VERSION ""

NS_ :

BS_:

BU_: STEER DAS HANDCART STEER BMS_HV BMS_HV HANDCART HANDCART BMS_HV BMS_HV HANDCART DAS BMS_HV HANDCART HANDCART BMS_HV HANDCART BMS_HV STEER DAS HANDCART BMS_HV BMS_HV STEER HANDCART DAS BMS_HV BMS_HV HANDCART STEER BRUSA BMS_HV DAS HANDCART BMS_HV DAS HANDCART INVERTER_L BMS_HV DAS HANDCART INVERTER_L BMS_HV INVERTER_L BMS_HV DAS HANDCART INVERTER_L BMS_HV DAS HANDCART STEER HANDCART DAS STEER BMS_HV DAS HANDCART BMS_HV BMS_HV HANDCART HANDCART STEER HANDCART DAS BMS_HV BMS_HV TLM TLM HANDCART STEER HANDCART STEER TLM BMS_HV DAS STEER HANDCART BMS_HV DAS BMS_HV HANDCART HANDCART TLM STEER STEER DAS STEER BMS_HV DAS TLM BMS_HV STEER TLM STEER STEER TLM DAS TLM BMS_LV STEER TLM BMS_LV STEER BMS_HV DAS TLM BMS_LV DAS STEER STEER DAS DATA_LOGGER BMS_LV BMS_LV BMS_LV BMS_HV DAS TLM BMS_LV STEER STEER DAS BMS_LV BMS_LV STEER BMS_HV STEER DAS DAS STEER BMS_LV TLM STEER STEER DAS DAS HANDCART BRUSA BRUSA BMS_LV TLM HANDCART STEER STEER BRUSA DAS DAS HANDCART BMS_LV BMS_LW BRUSA STEER STEER BMS_HV DAS DAS HANDCART BMS_LV BMS_HW BMS_HV STEER STEER HANDCART DAS DAS BMS_HV BMS_LV DAS HANDCART STEER STEER BMS_HV DAS DAS HANDCART STEER STEER BMS_HV DAS BMS_LV HANDCART DAS HANDCART BMS_HV STEER BMS_HV HANDCART DAS HANDCART BMS_HV HANDCART BMS_HV BRUSA STEER HANDCART DAS HANDCART

BO_ 3 BMS_HV_JMP_TO_BLT: 0 Vector__XXX

BO_ 35 BMS_LV_JMP_TO_BLT: 0 Vector__XXX

BO_ 1029 STEER_VERSION: 5 Vector__XXX
 SG_ canlib_build_time : 8|32@1+ (1,0) [0|4294967295] "" Vector__XXX
 SG_ component_version : 0|8@1+ (1,0) [0|255] "" Vector__XXX

BO_ 1061 DAS_VERSION: 5 Vector__XXX
 SG_ canlib_build_time : 8|32@1+ (1,0) [0|4294967295] "" Vector__XXX
 SG_ component_version : 0|8@1+ (1,0) [0|255] "" Vector__XXX

BO_ 1093 HV_VERSION: 5 Vector__XXX
 SG_ canlib_build_time : 8|32@1+ (1,0) [0|4294967295] "" Vector__XXX
 SG_ component_version : 0|8@1+ (1,0) [0|255] "" Vector__XXX

BO_ 1125 LV_VERSION: 5 Vector__XXX
 SG_ canlib_build_time : 8|32@1+ (1,0) [0|4294967295] "" Vector__XXX
 SG_ component_version : 0|8@1+ (1,0) [0|255] "" Vector__XXX

BO_ 1157 TLM_VERSION: 5 Vector__XXX
 SG_ canlib_build_time : 8|32@1+ (1,0) [0|4294967295] "" Vector__XXX
 SG_ component_version : 0|8@1+ (1,0) [0|255] "" Vector__XXX

BO_ 261 TIMESTAMP: 4 Vector__XXX
 SG_ timestamp : 0|32@1+ (1,0) [0|4294967295] "" Vector__XXX

BO_ 293 AMBIENT_TEMPERATURE: 2 Vector__XXX
 SG_ temp : 0|16@1- (1,-32768) [-32768|32767] "" Vector__XXX

BO_ 1072 DATA_LOGGER: 8 Vector__XXX
 SG_ placeholder2 : 32|32@1+ (1,0) [0|4294967295] "" Vector__XXX
 SG_ placeholder1 : 0|32@1+ (1,0) [0|4294967295] "" Vector__XXX

BO_ 256 SET_TLM_STATUS: 1 Vector__XXX
 SG_ tlm_status : 0|1@1+ (1,0) [0|1] "" Vector__XXX

BO_ 262 TLM_STATUS: 1 Vector__XXX
 SG_ tlm_status : 0|1@1+ (1,0) [0|1] "" Vector__XXX

BO_ 1792 STEER_SYSTEM_STATUS: 1 Vector__XXX
 SG_ soc_temp : 0|8@1+ (1,0) [0|255] "" Vector__XXX

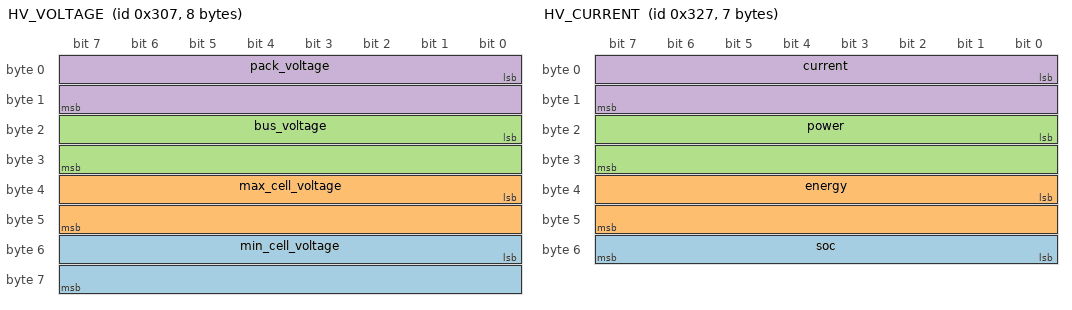
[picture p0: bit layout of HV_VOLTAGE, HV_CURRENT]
BO_ 775 HV_VOLTAGE: 8 Vector__XXX
 SG_ min_cell_voltage : 48|16@1+ (7.629510948348211e-05,0) [0|5] "" Vector__XXX
 SG_ max_cell_voltage : 32|16@1+ (7.629510948348211e-05,0) [0|5] "" Vector__XXX
 SG_ bus_voltage : 16|16@1+ (0.007019150072480354,0) [0|460] "" Vector__XXX
 SG_ pack_voltage : 0|16@1+ (0.007019150072480354,0) [0|460] "" Vector__XXX

BO_ 807 HV_CURRENT: 7 Vector__XXX
 SG_ soc : 48|8@1+ (0.39215686274509803,0) [0|100] "" Vector__XXX
 SG_ energy : 32|16@1+ (0.10681315327687495,0) [0|7000] "" Vector__XXX
 SG_ power : 16|16@1+ (0.0015259021896696422,0) [0|100] "" Vector__XXX
 SG_ current : 0|16@1+ (0.0032043945983062485,-10) [-10|200] "" Vector__XXX

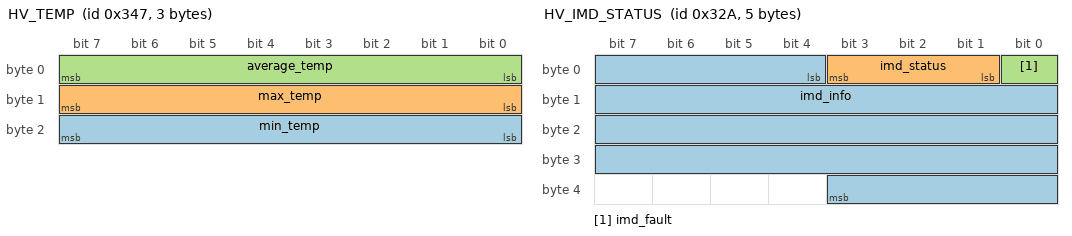
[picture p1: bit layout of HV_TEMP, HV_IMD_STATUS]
BO_ 839 HV_TEMP: 3 Vector__XXX
 SG_ min_temp : 16|8@1+ (0.39215686274509803,-20) [-20|80] "" Vector__XXX
 SG_ max_temp : 8|8@1+ (0.39215686274509803,-20) [-20|80] "" Vector__XXX
 SG_ average_temp : 0|8@1+ (0.39215686274509803,-20) [-20|80] "" Vector__XXX

BO_ 7 HV_ERRORS: 4 Vector__XXX
 SG_ errors_EEPROM_WRITE : 27|1@1+ (1,0) [0|0] "" Vector__XXX
 SG_ errors_EEPROM_COMM : 26|1@1+ (1,0) [0|0] "" Vector__XXX
 SG_ errors_FEEDBACK_CIRCUITRY : 25|1@1+ (1,0) [0|0] "" Vector__XXX
 SG_ errors_FEEDBACK : 24|1@1+ (1,0) [0|0] "" Vector__XXX
 SG_ errors_CELLBOARD_INTERNAL : 23|1@1+ (1,0) [0|0] "" Vector__XXX
 SG_ errors_CELLBOARD_COMM : 22|1@1+ (1,0) [0|0] "" Vector__XXX
 SG_ errors_INT_VOLTAGE_MISMATCH : 21|1@1+ (1,0) [0|0] "" Vector__XXX
 SG_ errors_CAN : 20|1@1+ (1,0) [0|0] "" Vector__XXX
 SG_ errors_OVER_CURRENT : 19|1@1+ (1,0) [0|0] "" Vector__XXX
 SG_ errors_CELL_OVER_TEMPERATURE : 18|1@1+ (1,0) [0|0] "" Vector__XXX
 SG_ errors_CELL_HIGH_TEMPERATURE : 17|1@1+ (1,0) [0|0] "" Vector__XXX
 SG_ errors_CELL_OVER_VOLTAGE : 16|1@1+ (1,0) [0|0] "" Vector__XXX
 SG_ errors_CELL_UNDER_VOLTAGE : 15|1@1+ (1,0) [0|0] "" Vector__XXX
 SG_ errors_CELL_LOW_VOLTAGE : 14|1@1+ (1,0) [0|0] "" Vector__XXX
 SG_ warnings_EEPROM_WRITE : 13|1@1+ (1,0) [0|0] "" Vector__XXX
 SG_ warnings_EEPROM_COMM : 12|1@1+ (1,0) [0|0] "" Vector__XXX
 SG_ warnings_FEEDBACK_CIRCUITRY : 11|1@1+ (1,0) [0|0] "" Vector__XXX
 SG_ warnings_FEEDBACK : 10|1@1+ (1,0) [0|0] "" Vector__XXX
 SG_ warnings_CELLBOARD_INTERNAL : 9|1@1+ (1,0) [0|0] "" Vector__XXX
 SG_ warnings_CELLBOARD_COMM : 8|1@1+ (1,0) [0|0] "" Vector__XXX
 SG_ warnings_INT_VOLTAGE_MISMATCH : 7|1@1+ (1,0) [0|0] "" Vector__XXX
 SG_ warnings_CAN : 6|1@1+ (1,0) [0|0] "" Vector__XXX
 SG_ warnings_OVER_CURRENT : 5|1@1+ (1,0) [0|0] "" Vector__XXX
 SG_ warnings_CELL_OVER_TEMPERATURE : 4|1@1+ (1,0) [0|0] "" Vector__XXX
 SG_ warnings_CELL_HIGH_TEMPERATURE : 3|1@1+ (1,0) [0|0] "" Vector__XXX
 SG_ warnings_CELL_OVER_VOLTAGE : 2|1@1+ (1,0) [0|0] "" Vector__XXX
 SG_ warnings_CELL_UNDER_VOLTAGE : 1|1@1+ (1,0) [0|0] "" Vector__XXX
 SG_ warnings_CELL_LOW_VOLTAGE : 0|1@1+ (1,0) [0|0] "" Vector__XXX

BO_ 1 HV_CAN_FORWARD: 1 Vector__XXX
 SG_ can_forward_set : 0|1@1+ (1,0) [0|1] "" Vector__XXX

BO_ 33 HV_FANS_OVERRIDE: 3 Vector__XXX
 SG_ fans_speed : 1|16@1+ (1.5259021896696422e-05,0) [0|1] "" Vector__XXX
 SG_ fans_override : 0|1@1+ (1,0) [0|1] "" Vector__XXX

BO_ 4 HV_CAN_FORWARD_STATUS: 1 Vector__XXX
 SG_ can_forward_status : 0|1@1+ (1,0) [0|1] "" Vector__XXX

BO_ 772 HV_FANS_OVERRIDE_STATUS: 3 Vector__XXX
 SG_ fans_speed : 1|16@1+ (1.5259021896696422e-05,0) [0|1] "" Vector__XXX
 SG_ fans_override : 0|1@1+ (1,0) [0|1] "" Vector__XXX

BO_ 778 HV_FEEDBACKS_STATUS: 5 Vector__XXX
 SG_ is_circuitry_error_FEEDBACK_SD_END : 37|1@1+ (1,0) [0|0] "" Vector__XXX
 SG_ is_circuitry_error_FEEDBACK_IMD_FAULT : 36|1@1+ (1,0) [0|0] "" Vector__XXX
 SG_ is_circuitry_error_FEEDBACK_RELAY_SD : 35|1@1+ (1,0) [0|0] "" Vector__XXX
 SG_ is_circuitry_error_FEEDBACK_SD_OUT : 34|1@1+ (1,0) [0|0] "" Vector__XXX
 SG_ is_circuitry_error_FEEDBACK_SD_IN : 33|1@1+ (1,0) [0|0] "" Vector__XXX
 SG_ is_circuitry_error_FEEDBACK_CHECK_MUX : 32|1@1+ (1,0) [0|0] "" Vector__XXX
 SG_ is_circuitry_error_FEEDBACK_TSP_OVER_60V_STATUS : 31|1@1+ (1,0) [0|0] "" Vector__XXX
 SG_ is_circuitry_error_FEEDBACK_PRECHARGE_STATUS : 30|1@1+ (1,0) [0|0] "" Vector__XXX
 SG_ is_circuitry_error_FEEDBACK_AIRN_GATE : 29|1@1+ (1,0) [0|0] "" Vector__XXX
 SG_ is_circuitry_error_FEEDBACK_AIRP_GATE : 28|1@1+ (1,0) [0|0] "" Vector__XXX
 SG_ is_circuitry_error_FEEDBACK_AIRP_STATUS : 27|1@1+ (1,0) [0|0] "" Vector__XXX
 SG_ is_circuitry_error_FEEDBACK_AIRN_STATUS : 26|1@1+ (1,0) [0|0] "" Vector__XXX
 SG_ is_circuitry_error_FEEDBACK_TS_OVER_60V_STATUS : 25|1@1+ (1,0) [0|0] "" Vector__XXX
 SG_ is_circuitry_error_FEEDBACK_TSAL_GREEN : 24|1@1+ (1,0) [0|0] "" Vector__XXX
 SG_ is_circuitry_error_FEEDBACK_EXT_LATCHED : 23|1@1+ (1,0) [0|0] "" Vector__XXX
 SG_ is_circuitry_error_FEEDBACK_BMS_LATCHED : 22|1@1+ (1,0) [0|0] "" Vector__XXX
 SG_ is_circuitry_error_FEEDBACK_TSAL_GREEN_FAULT_LATCHED : 21|1@1+ (1,0) [0|0] "" Vector__XXX
 SG_ is_circuitry_error_FEEDBACK_IMD_LATCHED : 20|1@1+ (1,0) [0|0] "" Vector__XXX
 SG_ is_circuitry_error_FEEDBACK_TSAL_GREEN_FAULT : 19|1@1+ (1,0) [0|0] "" Vector__XXX
 SG_ feedbacks_status_FEEDBACK_SD_END : 18|1@1+ (1,0) [0|0] "" Vector__XXX
 SG_ feedbacks_status_FEEDBACK_IMD_FAULT : 17|1@1+ (1,0) [0|0] "" Vector__XXX
 SG_ feedbacks_status_FEEDBACK_RELAY_SD : 16|1@1+ (1,0) [0|0] "" Vector__XXX
 SG_ feedbacks_status_FEEDBACK_SD_OUT : 15|1@1+ (1,0) [0|0] "" Vector__XXX
 SG_ feedbacks_status_FEEDBACK_SD_IN : 14|1@1+ (1,0) [0|0] "" Vector__XXX
 SG_ feedbacks_status_FEEDBACK_CHECK_MUX : 13|1@1+ (1,0) [0|0] "" Vector__XXX
 SG_ feedbacks_status_FEEDBACK_TSP_OVER_60V_STATUS : 12|1@1+ (1,0) [0|0] "" Vector__XXX
 SG_ feedbacks_status_FEEDBACK_PRECHARGE_STATUS : 11|1@1+ (1,0) [0|0] "" Vector__XXX
 SG_ feedbacks_status_FEEDBACK_AIRN_GATE : 10|1@1+ (1,0) [0|0] "" Vector__XXX
 SG_ feedbacks_status_FEEDBACK_AIRP_GATE : 9|1@1+ (1,0) [0|0] "" Vector__XXX
 SG_ feedbacks_status_FEEDBACK_AIRP_STATUS : 8|1@1+ (1,0) [0|0] "" Vector__XXX
 SG_ feedbacks_status_FEEDBACK_AIRN_STATUS : 7|1@1+ (1,0) [0|0] "" Vector__XXX
 SG_ feedbacks_status_FEEDBACK_TS_OVER_60V_STATUS : 6|1@1+ (1,0) [0|0] "" Vector__XXX
 SG_ feedbacks_status_FEEDBACK_TSAL_GREEN : 5|1@1+ (1,0) [0|0] "" Vector__XXX
 SG_ feedbacks_status_FEEDBACK_EXT_LATCHED : 4|1@1+ (1,0) [0|0] "" Vector__XXX
 SG_ feedbacks_status_FEEDBACK_BMS_LATCHED : 3|1@1+ (1,0) [0|0] "" Vector__XXX
 SG_ feedbacks_status_FEEDBACK_TSAL_GREEN_FAULT_LATCHED : 2|1@1+ (1,0) [0|0] "" Vector__XXX
 SG_ feedbacks_status_FEEDBACK_IMD_LATCHED : 1|1@1+ (1,0) [0|0] "" Vector__XXX
 SG_ feedbacks_status_FEEDBACK_TSAL_GREEN_FAULT : 0|1@1+ (1,0) [0|0] "" Vector__XXX

BO_ 810 HV_IMD_STATUS: 5 Vector__XXX
 SG_ imd_info : 4|32@1- (1,-2147483648) [-2147483648|2147483647] "" Vector__XXX
 SG_ imd_status : 1|3@1+ (1,0) [0|7] "" Vector__XXX
 SG_ imd_fault : 0|1@1+ (1,0) [0|1] "" Vector__XXX

BO_ 39 TS_STATUS: 1 Vector__XXX
 SG_ ts_status : 0|2@1+ (1,0) [0|3] "" Vector__XXX

BO_ 65 SET_TS_STATUS_DAS: 1 Vector__XXX
 SG_ ts_status_set : 0|1@1+ (1,0) [0|1] "" Vector__XXX

BO_ 97 SET_TS_STATUS_HANDCART: 1 Vector__XXX
 SG_ ts_status_set : 0|1@1+ (1,0) [0|1] "" Vector__XXX

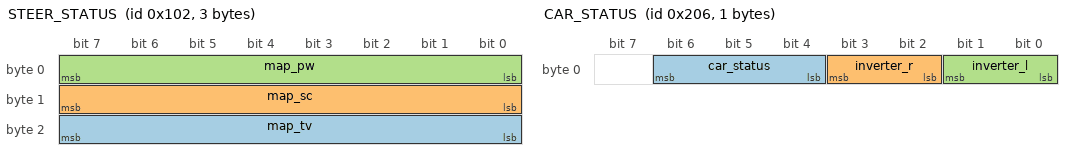
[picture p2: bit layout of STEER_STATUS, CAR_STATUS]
BO_ 258 STEER_STATUS: 3 Vector__XXX
 SG_ map_tv : 16|8@1+ (0.06666666666666667,0) [0|1] "" Vector__XXX
 SG_ map_sc : 8|8@1+ (0.06666666666666667,0) [0|1] "" Vector__XXX
 SG_ map_pw : 0|8@1+ (0.1,-0.5) [-0.5|1] "" Vector__XXX

BO_ 770 SET_CAR_STATUS: 1 Vector__XXX
 SG_ car_status_set : 0|2@1+ (1,0) [0|3] "" Vector__XXX

BO_ 1026 SET_PEDALS_RANGE: 1 Vector__XXX
 SG_ pedal : 1|1@1+ (1,0) [0|1] "" Vector__XXX
 SG_ bound : 0|1@1+ (1,0) [0|1] "" Vector__XXX

BO_ 1058 SET_STEERING_ANGLE_RANGE: 1 Vector__XXX
 SG_ bound : 0|1@1+ (1,0) [0|1] "" Vector__XXX

BO_ 518 CAR_STATUS: 1 Vector__XXX
 SG_ car_status : 4|3@1+ (1,0) [0|7] "" Vector__XXX
 SG_ inverter_r : 2|2@1+ (1,0) [0|3] "" Vector__XXX
 SG_ inverter_l : 0|2@1+ (1,0) [0|3] "" Vector__XXX

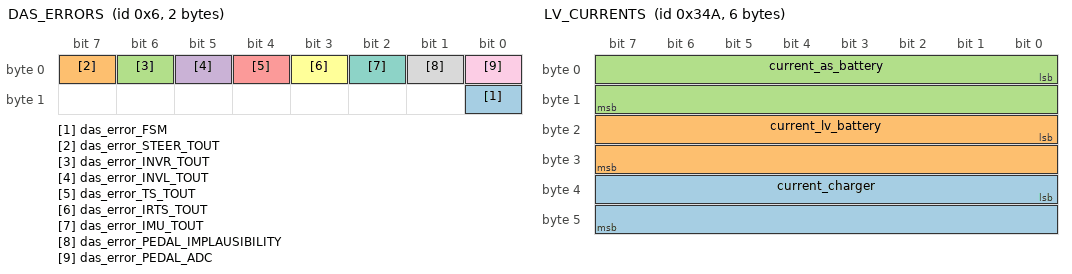
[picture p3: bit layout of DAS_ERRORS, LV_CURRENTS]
BO_ 6 DAS_ERRORS: 2 Vector__XXX
 SG_ das_error_FSM : 8|1@1+ (1,0) [0|0] "" Vector__XXX
 SG_ das_error_STEER_TOUT : 7|1@1+ (1,0) [0|0] "" Vector__XXX
 SG_ das_error_INVR_TOUT : 6|1@1+ (1,0) [0|0] "" Vector__XXX
 SG_ das_error_INVL_TOUT : 5|1@1+ (1,0) [0|0] "" Vector__XXX
 SG_ das_error_TS_TOUT : 4|1@1+ (1,0) [0|0] "" Vector__XXX
 SG_ das_error_IRTS_TOUT : 3|1@1+ (1,0) [0|0] "" Vector__XXX
 SG_ das_error_IMU_TOUT : 2|1@1+ (1,0) [0|0] "" Vector__XXX
 SG_ das_error_PEDAL_IMPLAUSIBILITY : 1|1@1+ (1,0) [0|0] "" Vector__XXX
 SG_ das_error_PEDAL_ADC : 0|1@1+ (1,0) [0|0] "" Vector__XXX

BO_ 842 LV_CURRENTS: 6 Vector__XXX
 SG_ current_charger : 32|16@1+ (0.0009155413138017853,-30) [-30|30] "" Vector__XXX
 SG_ current_lv_battery : 16|16@1+ (0.0009155413138017853,-10) [-10|50] "" Vector__XXX
 SG_ current_as_battery : 0|16@1+ (0.0009155413138017853,-10) [-10|50] "" Vector__XXX

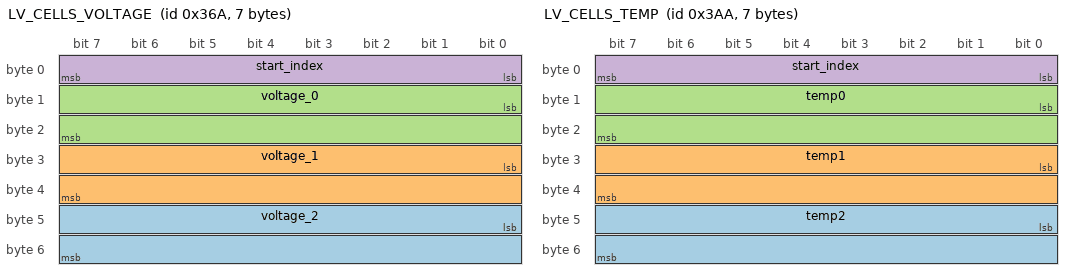
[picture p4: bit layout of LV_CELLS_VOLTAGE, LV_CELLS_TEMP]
BO_ 874 LV_CELLS_VOLTAGE: 7 Vector__XXX
 SG_ voltage_2 : 40|16@1+ (7.629510948348211e-05,0) [0|5] "" Vector__XXX
 SG_ voltage_1 : 24|16@1+ (7.629510948348211e-05,0) [0|5] "" Vector__XXX
 SG_ voltage_0 : 8|16@1+ (7.629510948348211e-05,0) [0|5] "" Vector__XXX
 SG_ start_index : 0|8@1+ (1,0) [0|255] "" Vector__XXX

BO_ 906 LV_TOTAL_VOLTAGE: 4 Vector__XXX
 SG_ total_voltage : 0|32@1+ (9.918250725748923e-05,0) [0|26] "" Vector__XXX

BO_ 938 LV_CELLS_TEMP: 7 Vector__XXX
 SG_ temp2 : 40|16@1+ (0.0061038881767686015,-20) [-20|80] "" Vector__XXX
 SG_ temp1 : 24|16@1+ (0.0061038881767686015,-20) [-20|80] "" Vector__XXX
 SG_ temp0 : 8|16@1+ (0.0061038881767686015,-20) [-20|80] "" Vector__XXX
 SG_ start_index : 0|8@1+ (1,0) [0|255] "" Vector__XXX

BO_ 970 COOLING_STATUS: 4 Vector__XXX
 SG_ pumps_speed : 16|16@1+ (3.0518043793392844e-05,-1) [-1|1] "" Vector__XXX
 SG_ radiators_speed : 0|16@1+ (3.0518043793392844e-05,-1) [-1|1] "" Vector__XXX

BO_ 777 SET_RADIATOR_SPEED: 2 Vector__XXX
 SG_ radiators_speed : 0|16@1+ (3.0518043793392844e-05,-1) [-1|1] "" Vector__XXX

BO_ 809 SET_PUMPS_SPEED: 2 Vector__XXX
 SG_ pumps_speed : 0|16@1+ (3.0518043793392844e-05,-1) [-1|1] "" Vector__XXX

BO_ 265 SET_INVERTER_CONNECTION_STATUS: 1 Vector__XXX
 SG_ status : 0|1@1+ (1,0) [0|1] "" Vector__XXX

BO_ 266 INVERTER_CONNECTION_STATUS: 1 Vector__XXX
 SG_ status : 0|1@1+ (1,0) [0|1] "" Vector__XXX

BO_ 522 LV_ERRORS: 5 Vector__XXX
 SG_ errors_MUX : 33|1@1+ (1,0) [0|0] "" Vector__XXX
 SG_ errors_ADC_INIT : 32|1@1+ (1,0) [0|0] "" Vector__XXX
 SG_ errors_PUMP : 31|1@1+ (1,0) [0|0] "" Vector__XXX
 SG_ errors_FAN : 30|1@1+ (1,0) [0|0] "" Vector__XXX
 SG_ errors_RADIATOR : 29|1@1+ (1,0) [0|0] "" Vector__XXX
 SG_ errors_MCP23017 : 28|1@1+ (1,0) [0|0] "" Vector__XXX
 SG_ errors_VOLTAGES_NOT_READY : 27|1@1+ (1,0) [0|0] "" Vector__XXX
 SG_ errors_BMS_MONITOR : 26|1@1+ (1,0) [0|0] "" Vector__XXX
 SG_ errors_RELAY : 25|1@1+ (1,0) [0|0] "" Vector__XXX
 SG_ errors_CELL_OVER_TEMPERATURE : 24|1@1+ (1,0) [0|0] "" Vector__XXX
 SG_ errors_CELL_UNDER_TEMPERATURE : 23|1@1+ (1,0) [0|0] "" Vector__XXX
 SG_ errors_OVER_CURRENT : 22|1@1+ (1,0) [0|0] "" Vector__XXX
 SG_ errors_SPI : 21|1@1+ (1,0) [0|0] "" Vector__XXX
 SG_ errors_CAN : 20|1@1+ (1,0) [0|0] "" Vector__XXX
 SG_ errors_BATTERY_OPEN_WIRE : 19|1@1+ (1,0) [0|0] "" Vector__XXX
 SG_ errors_CELL_OVERVOLTAGE : 18|1@1+ (1,0) [0|0] "" Vector__XXX
 SG_ errors_CELL_UNDERVOLTAGE : 17|1@1+ (1,0) [0|0] "" Vector__XXX
 SG_ warnings_MUX : 16|1@1+ (1,0) [0|0] "" Vector__XXX
 SG_ warnings_ADC_INIT : 15|1@1+ (1,0) [0|0] "" Vector__XXX
 SG_ warnings_PUMP : 14|1@1+ (1,0) [0|0] "" Vector__XXX
 SG_ warnings_FAN : 13|1@1+ (1,0) [0|0] "" Vector__XXX
 SG_ warnings_RADIATOR : 12|1@1+ (1,0) [0|0] "" Vector__XXX
 SG_ warnings_MCP23017 : 11|1@1+ (1,0) [0|0] "" Vector__XXX
 SG_ warnings_VOLTAGES_NOT_READY : 10|1@1+ (1,0) [0|0] "" Vector__XXX
 SG_ warnings_BMS_MONITOR : 9|1@1+ (1,0) [0|0] "" Vector__XXX
 SG_ warnings_RELAY : 8|1@1+ (1,0) [0|0] "" Vector__XXX
 SG_ warnings_CELL_OVER_TEMPERATURE : 7|1@1+ (1,0) [0|0] "" Vector__XXX
 SG_ warnings_CELL_UNDER_TEMPERATURE : 6|1@1+ (1,0) [0|0] "" Vector__XXX
 SG_ warnings_OVER_CURRENT : 5|1@1+ (1,0) [0|0] "" Vector__XXX
 SG_ warnings_SPI : 4|1@1+ (1,0) [0|0] "" Vector__XXX
 SG_ warnings_CAN : 3|1@1+ (1,0) [0|0] "" Vector__XXX
 SG_ warnings_BATTERY_OPEN_WIRE : 2|1@1+ (1,0) [0|0] "" Vector__XXX
 SG_ warnings_CELL_OVERVOLTAGE : 1|1@1+ (1,0) [0|0] "" Vector__XXX
 SG_ warnings_CELL_UNDERVOLTAGE : 0|1@1+ (1,0) [0|0] "" Vector__XXX

BO_ 298 LV_FEEDBACKS: 7 Vector__XXX
 SG_ sd_end : 35|16@1+ (0.005862237420615535,0) [0|12] "" Vector__XXX
 SG_ sd_start : 19|16@1+ (0.005862237420615535,0) [0|12] "" Vector__XXX
 SG_ feedbacks_AS_ACTUATION_FB : 18|1@1+ (1,0) [0|0] "" Vector__XXX
 SG_ feedbacks_FAN_FB : 17|1@1+ (1,0) [0|0] "" Vector__XXX
 SG_ feedbacks_RADIATORS_FB : 16|1@1+ (1,0) [0|0] "" Vector__XXX
 SG_ feedbacks_SHUTDOWN_FB : 15|1@1+ (1,0) [0|0] "" Vector__XXX
 SG_ feedbacks_PUMPS_FB : 14|1@1+ (1,0) [0|0] "" Vector__XXX
 SG_ feedbacks_PCBS_FB : 13|1@1+ (1,0) [0|0] "" Vector__XXX
 SG_ feedbacks_INVERTERS_FB : 12|1@1+ (1,0) [0|0] "" Vector__XXX
 SG_ feedbacks_INTERLOCK_FB : 11|1@1+ (1,0) [0|0] "" Vector__XXX
 SG_ feedbacks_ASMS_FB : 10|1@1+ (1,0) [0|0] "" Vector__XXX
 SG_ feedbacks_AMS_FB : 9|1@1+ (1,0) [0|0] "" Vector__XXX
 SG_ feedbacks_HVD_FB : 8|1@1+ (1,0) [0|0] "" Vector__XXX
 SG_ feedbacks_BACK_PLATE_FB : 7|1@1+ (1,0) [0|0] "" Vector__XXX
 SG_ feedbacks_HV_ENCL_2_FB : 6|1@1+ (1,0) [0|0] "" Vector__XXX
 SG_ feedbacks_HV_ENCL_1_FB : 5|1@1+ (1,0) [0|0] "" Vector__XXX
 SG_ feedbacks_LV_ENCL : 4|1@1+ (1,0) [0|0] "" Vector__XXX
 SG_ feedbacks_RES_FB : 3|1@1+ (1,0) [0|0] "" Vector__XXX
 SG_ feedbacks_LVMS_FB : 2|1@1+ (1,0) [0|0] "" Vector__XXX
 SG_ feedbacks_IMD_FB : 1|1@1+ (1,0) [0|0] "" Vector__XXX
 SG_ feedbacks_BSPD_FB : 0|1@1+ (1,0) [0|0] "" Vector__XXX

BO_ 330 SHUTDOWN_STATUS: 1 Vector__XXX
 SG_ output : 1|1@1+ (1,0) [0|1] "" Vector__XXX
 SG_ input : 0|1@1+ (1,0) [0|1] "" Vector__XXX

BO_ 0 MARKER: 0 Vector__XXX

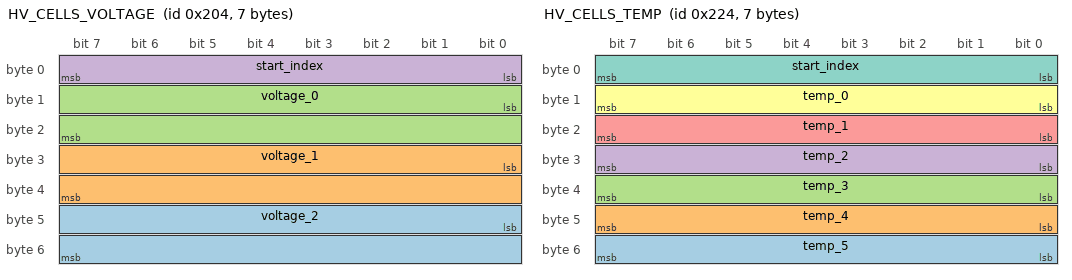
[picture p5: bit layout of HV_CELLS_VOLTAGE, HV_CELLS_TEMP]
BO_ 516 HV_CELLS_VOLTAGE: 7 Vector__XXX
 SG_ voltage_2 : 40|16@1+ (7.629510948348211e-05,0) [0|5] "" Vector__XXX
 SG_ voltage_1 : 24|16@1+ (7.629510948348211e-05,0) [0|5] "" Vector__XXX
 SG_ voltage_0 : 8|16@1+ (7.629510948348211e-05,0) [0|5] "" Vector__XXX
 SG_ start_index : 0|8@1+ (1,0) [0|255] "" Vector__XXX

BO_ 548 HV_CELLS_TEMP: 7 Vector__XXX
 SG_ temp_5 : 48|8@1+ (0.39215686274509803,-20) [-20|80] "" Vector__XXX
 SG_ temp_4 : 40|8@1+ (0.39215686274509803,-20) [-20|80] "" Vector__XXX
 SG_ temp_3 : 32|8@1+ (0.39215686274509803,-20) [-20|80] "" Vector__XXX
 SG_ temp_2 : 24|8@1+ (0.39215686274509803,-20) [-20|80] "" Vector__XXX
 SG_ temp_1 : 16|8@1+ (0.39215686274509803,-20) [-20|80] "" Vector__XXX
 SG_ temp_0 : 8|8@1+ (0.39215686274509803,-20) [-20|80] "" Vector__XXX
 SG_ start_index : 0|8@1+ (1,0) [0|255] "" Vector__XXX

BO_ 580 HV_CELL_BALANCING_STATUS: 1 Vector__XXX
 SG_ balancing_status : 0|1@1+ (1,0) [0|1] "" Vector__XXX

BO_ 545 SET_CELL_BALANCING_STATUS: 1 Vector__XXX
 SG_ set_balancing_status : 0|1@1+ (1,0) [0|1] "" Vector__XXX

BO_ 769 HANDCART_STATUS: 1 Vector__XXX
 SG_ connected : 0|1@1+ (1,0) [0|1] "" Vector__XXX

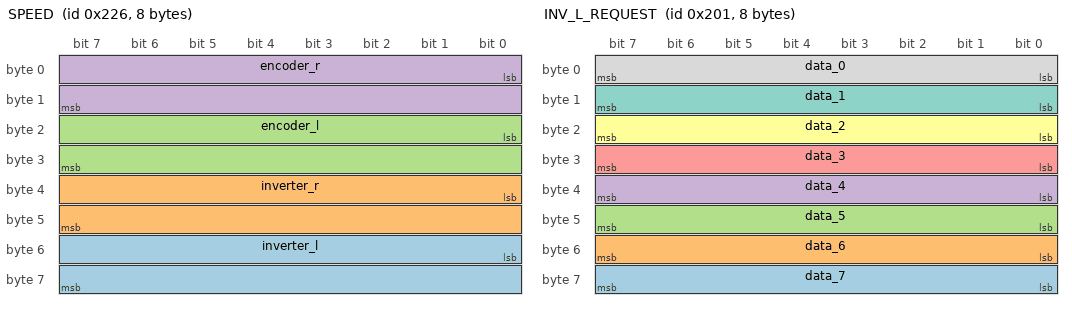
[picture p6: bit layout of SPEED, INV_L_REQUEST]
BO_ 550 SPEED: 8 Vector__XXX
 SG_ inverter_l : 48|16@1+ (0.006103608758678569,-200) [-200|200] "" Vector__XXX
 SG_ inverter_r : 32|16@1+ (0.006103608758678569,-200) [-200|200] "" Vector__XXX
 SG_ encoder_l : 16|16@1+ (0.006103608758678569,-200) [-200|200] "" Vector__XXX
 SG_ encoder_r : 0|16@1+ (0.006103608758678569,-200) [-200|200] "" Vector__XXX

BO_ 513 INV_L_REQUEST: 8 Vector__XXX
 SG_ data_7 : 56|8@1+ (1,0) [0|255] "" Vector__XXX
 SG_ data_6 : 48|8@1+ (1,0) [0|255] "" Vector__XXX
 SG_ data_5 : 40|8@1+ (1,0) [0|255] "" Vector__XXX
 SG_ data_4 : 32|8@1+ (1,0) [0|255] "" Vector__XXX
 SG_ data_3 : 24|8@1+ (1,0) [0|255] "" Vector__XXX
 SG_ data_2 : 16|8@1+ (1,0) [0|255] "" Vector__XXX
 SG_ data_1 : 8|8@1+ (1,0) [0|255] "" Vector__XXX
 SG_ data_0 : 0|8@1+ (1,0) [0|255] "" Vector__XXX

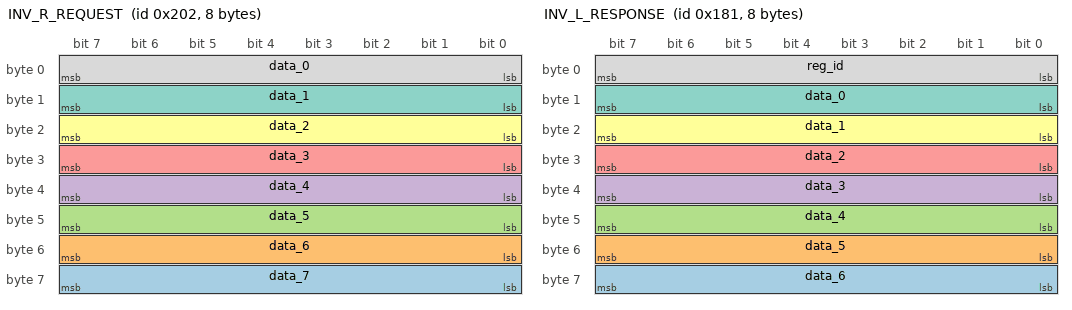
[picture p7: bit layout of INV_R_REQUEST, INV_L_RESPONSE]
BO_ 514 INV_R_REQUEST: 8 Vector__XXX
 SG_ data_7 : 56|8@1+ (1,0) [0|255] "" Vector__XXX
 SG_ data_6 : 48|8@1+ (1,0) [0|255] "" Vector__XXX
 SG_ data_5 : 40|8@1+ (1,0) [0|255] "" Vector__XXX
 SG_ data_4 : 32|8@1+ (1,0) [0|255] "" Vector__XXX
 SG_ data_3 : 24|8@1+ (1,0) [0|255] "" Vector__XXX
 SG_ data_2 : 16|8@1+ (1,0) [0|255] "" Vector__XXX
 SG_ data_1 : 8|8@1+ (1,0) [0|255] "" Vector__XXX
 SG_ data_0 : 0|8@1+ (1,0) [0|255] "" Vector__XXX

BO_ 385 INV_L_RESPONSE: 8 Vector__XXX
 SG_ data_6 : 56|8@1+ (1,0) [0|255] "" Vector__XXX
 SG_ data_5 : 48|8@1+ (1,0) [0|255] "" Vector__XXX
 SG_ data_4 : 40|8@1+ (1,0) [0|255] "" Vector__XXX
 SG_ data_3 : 32|8@1+ (1,0) [0|255] "" Vector__XXX
 SG_ data_2 : 24|8@1+ (1,0) [0|255] "" Vector__XXX
 SG_ data_1 : 16|8@1+ (1,0) [0|255] "" Vector__XXX
 SG_ data_0 : 8|8@1+ (1,0) [0|255] "" Vector__XXX
 SG_ reg_id : 0|8@1+ (1,0) [0|255] "" Vector__XXX

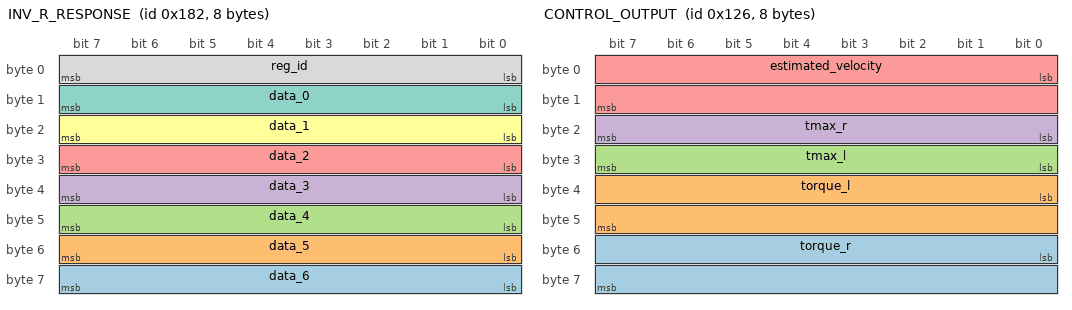
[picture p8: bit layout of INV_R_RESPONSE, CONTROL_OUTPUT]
BO_ 386 INV_R_RESPONSE: 8 Vector__XXX
 SG_ data_6 : 56|8@1+ (1,0) [0|255] "" Vector__XXX
 SG_ data_5 : 48|8@1+ (1,0) [0|255] "" Vector__XXX
 SG_ data_4 : 40|8@1+ (1,0) [0|255] "" Vector__XXX
 SG_ data_3 : 32|8@1+ (1,0) [0|255] "" Vector__XXX
 SG_ data_2 : 24|8@1+ (1,0) [0|255] "" Vector__XXX
 SG_ data_1 : 16|8@1+ (1,0) [0|255] "" Vector__XXX
 SG_ data_0 : 8|8@1+ (1,0) [0|255] "" Vector__XXX
 SG_ reg_id : 0|8@1+ (1,0) [0|255] "" Vector__XXX

BO_ 16 FLASH_CELLBOARD_0_TX: 0 Vector__XXX

BO_ 17 FLASH_CELLBOARD_0_RX: 0 Vector__XXX

BO_ 18 FLASH_CELLBOARD_1_TX: 0 Vector__XXX

BO_ 19 FLASH_CELLBOARD_1_RX: 0 Vector__XXX

BO_ 20 FLASH_CELLBOARD_2_TX: 0 Vector__XXX

BO_ 21 FLASH_CELLBOARD_2_RX: 0 Vector__XXX

BO_ 22 FLASH_CELLBOARD_3_TX: 0 Vector__XXX

BO_ 23 FLASH_CELLBOARD_3_RX: 0 Vector__XXX

BO_ 24 FLASH_CELLBOARD_4_TX: 0 Vector__XXX

BO_ 25 FLASH_CELLBOARD_4_RX: 0 Vector__XXX

BO_ 26 FLASH_CELLBOARD_5_TX: 0 Vector__XXX

BO_ 27 FLASH_CELLBOARD_5_RX: 0 Vector__XXX

BO_ 2017 FLASH_BMS_HV_TX: 0 Vector__XXX

BO_ 1639 FLASH_BMS_HV_RX: 0 Vector__XXX

BO_ 2033 FLASH_BMS_LV_TX: 0 Vector__XXX

BO_ 1655 FLASH_BMS_LV_RX: 0 Vector__XXX

BO_ 618 BRUSA_NLG5_CTL: 0 Vector__XXX

BO_ 610 BRUSA_ST: 0 Vector__XXX

BO_ 611 BRUSA_ACT_I: 0 Vector__XXX

BO_ 612 BRUSA_ACT_II: 0 Vector__XXX

BO_ 613 BRUSA_TEMP: 0 Vector__XXX

BO_ 614 BRUSA_ERR: 0 Vector__XXX

BO_ 294 CONTROL_OUTPUT: 8 Vector__XXX
 SG_ torque_r : 48|16@1+ (0.0012207217517357137,0) [0|80] "" Vector__XXX
 SG_ torque_l : 32|16@1+ (0.0012207217517357137,0) [0|80] "" Vector__XXX
 SG_ tmax_l : 24|8@1+ (0.3137254901960784,0) [0|80] "" Vector__XXX
 SG_ tmax_r : 16|8@1+ (0.3137254901960784,0) [0|80] "" Vector__XXX
 SG_ estimated_velocity : 0|16@1+ (0.0009155413138017853,-10) [-10|50] "" Vector__XXX

BO_ 520 LC_RESET: 0 Vector__XXX

CM_ BO_ 1029 "periodic message containing current can definitions version";
CM_ BO_ 1061 "periodic message containing current can definitions version";
CM_ BO_ 1093 "periodic message containing current can definitions version";
CM_ BO_ 1125 "periodic message containing current can definitions version";
CM_ BO_ 1157 "periodic message containing current can definitions version";
CM_ BO_ 261 "every second unix encoded time and date used by logging devices to sync";
CM_ BO_ 293 "ambient temperature as send from IMU";
CM_ BO_ 1072 "data logger message";
CM_ BO_ 256 "Ask telemetry to turn on/off and send a tuple containing the current{test, driver, map); only once";
CM_ BO_ 262 "The answer to the steering wheel's message that changes the status of the telemetry";
CM_ BO_ 1792 "System stats of the raspberry pi inside the steering wheel";
CM_ BO_ 775 "Pack stats";
CM_ BO_ 807 "Current and power supplied by the pack, energy and state of charge of the pack";
CM_ BO_ 839 "Cell temperatures";
CM_ BO_ 7 "Battery-related errors";
CM_ BO_ 1 "Enable/disable can forwarding to internal bms network";
CM_ BO_ 33 "override fans speed";
CM_ BO_ 4 "Status of can forwarding to internal bms network";
CM_ BO_ 772 "Status of fans override";
CM_ BO_ 778 "Errors on the feedbacks checks";
CM_ BO_ 810 "Status of fans override";
CM_ BO_ 39 "BMS status";
CM_ BO_ 65 "Requests a TS status; only once";
CM_ BO_ 97 "Requests a TS status; only once";
CM_ BO_ 258 "Send update of the tuneable values from the steering wheel";
CM_ BO_ 770 "Ask to DAS to change car status; only once";
CM_ BO_ 1026 "Ask to calibrate pedals by specifying which pedal to calibrate and if the value is max or min";
CM_ BO_ 1058 "Ask to calibrate steering encoder by specifying if the value is max or min";
CM_ BO_ 518 "Car status, all states managed by the DAS will be send (car status, inverters status)";
CM_ BO_ 6 "DAS errors messages";
CM_ BO_ 842 "Currents of AS Battery system, LV Battery and Charger";
CM_ BO_ 874 "LV Voltages for each cell";
CM_ BO_ 906 "Voltage of LV battery pack";
CM_ BO_ 938 "Temperature °C for each cell";
CM_ BO_ 970 "Percentage value from 0% to 100% of radiator fans and pumps speed, 8bit";
CM_ BO_ 777 "Set both radiators speed";
CM_ BO_ 809 "Set both pumps speed";
CM_ BO_ 265 "Set the status of the inverter inputs RFE and RUN";
CM_ BO_ 266 "Inverter status";
CM_ BO_ 522 "LV Battery-related errors";
CM_ BO_ 298 "LV Battery-related errors";
CM_ BO_ 330 "Shutdown status";
CM_ BO_ 0 "Send a marker to telemetry";
CM_ BO_ 516 "Voltages for each cell";
CM_ BO_ 548 "Cell temperatures";
CM_ BO_ 580 "Cell balancing status";
CM_ BO_ 545 "Set cell balancing status; only once";
CM_ BO_ 769 "Sends updates on the presence of the handcart";
CM_ BO_ 550 "Encoder and inverter speed in rad/sec";
CM_ BO_ 294 "Control output, N*m";
BA_DEF_ BO_  "GenMsgCycleTime" INT 0 65535;
BA_DEF_DEF_  "GenMsgCycleTime" 0;
BA_ "GenMsgCycleTime" BO_ 1029 1000;
BA_ "GenMsgCycleTime" BO_ 1061 1000;
BA_ "GenMsgCycleTime" BO_ 1093 1000;
BA_ "GenMsgCycleTime" BO_ 1125 1000;
BA_ "GenMsgCycleTime" BO_ 1157 1000;
BA_ "GenMsgCycleTime" BO_ 261 1000;
BA_ "GenMsgCycleTime" BO_ 293 1000;
BA_ "GenMsgCycleTime" BO_ 1072 1000;
BA_ "GenMsgCycleTime" BO_ 262 1000;
BA_ "GenMsgCycleTime" BO_ 1792 1000;
BA_ "GenMsgCycleTime" BO_ 775 10;
BA_ "GenMsgCycleTime" BO_ 807 10;
BA_ "GenMsgCycleTime" BO_ 839 100;
BA_ "GenMsgCycleTime" BO_ 7 10;
BA_ "GenMsgCycleTime" BO_ 39 10;
BA_ "GenMsgCycleTime" BO_ 65 100;
BA_ "GenMsgCycleTime" BO_ 97 100;
BA_ "GenMsgCycleTime" BO_ 258 100;
BA_ "GenMsgCycleTime" BO_ 518 100;
BA_ "GenMsgCycleTime" BO_ 6 10;
BA_ "GenMsgCycleTime" BO_ 842 500;
BA_ "GenMsgCycleTime" BO_ 874 100;
BA_ "GenMsgCycleTime" BO_ 906 100;
BA_ "GenMsgCycleTime" BO_ 938 100;
BA_ "GenMsgCycleTime" BO_ 970 1000;
BA_ "GenMsgCycleTime" BO_ 265 100;
BA_ "GenMsgCycleTime" BO_ 266 100;
BA_ "GenMsgCycleTime" BO_ 522 10;
BA_ "GenMsgCycleTime" BO_ 298 10;
BA_ "GenMsgCycleTime" BO_ 330 500;
BA_ "GenMsgCycleTime" BO_ 516 100;
BA_ "GenMsgCycleTime" BO_ 548 100;
BA_ "GenMsgCycleTime" BO_ 580 500;
BA_ "GenMsgCycleTime" BO_ 769 500;
BA_ "GenMsgCycleTime" BO_ 550 10;
BA_ "GenMsgCycleTime" BO_ 513 10;
BA_ "GenMsgCycleTime" BO_ 514 10;
BA_ "GenMsgCycleTime" BO_ 385 100;
BA_ "GenMsgCycleTime" BO_ 386 100;
BA_ "GenMsgCycleTime" BO_ 294 100;
VAL_ 256 tlm_status 0 "OFF" 1 "ON" ;
VAL_ 262 tlm_status 0 "OFF" 1 "ON" ;
VAL_ 1 can_forward_set 0 "OFF" 1 "ON" ;
VAL_ 33 fans_override 0 "OFF" 1 "ON" ;
VAL_ 4 can_forward_status 0 "OFF" 1 "ON" ;
VAL_ 772 fans_override 0 "OFF" 1 "ON" ;
VAL_ 810 imd_status 0 "IMD_SC" 1 "IMD_NORMAL" 2 "IMD_UNDER_VOLTAGE" 3 "IMD_START_MEASURE" 4 "IMD_DEVICE_ERROR" 5 "IMD_EARTH_FAULT" ;
VAL_ 39 ts_status 0 "OFF" 1 "PRECHARGE" 2 "ON" 3 "FATAL" ;
VAL_ 65 ts_status_set 0 "OFF" 1 "ON" ;
VAL_ 97 ts_status_set 0 "OFF" 1 "ON" ;
VAL_ 770 car_status_set 0 "IDLE" 1 "READY" 2 "DRIVE" ;
VAL_ 1026 pedal 0 "ACCELERATOR" 1 "BRAKE" ;
VAL_ 1026 bound 0 "SET_MAX" 1 "SET_MIN" ;
VAL_ 1058 bound 0 "SET_MAX" 1 "SET_MIN" ;
VAL_ 518 car_status 0 "IDLE" 1 "PRE_SETUP" 2 "TS_ON" 3 "POST_SETUP" 4 "DRIVE" 5 "TEARDOWN" ;
VAL_ 518 inverter_r 0 "OFF" 1 "IDLE" 2 "ON" ;
VAL_ 518 inverter_l 0 "OFF" 1 "IDLE" 2 "ON" ;
VAL_ 265 status 0 "OFF" 1 "ON" ;
VAL_ 266 status 0 "OFF" 1 "ON" ;
VAL_ 580 balancing_status 0 "OFF" 1 "ON" ;
VAL_ 545 set_balancing_status 0 "OFF" 1 "ON" ;
